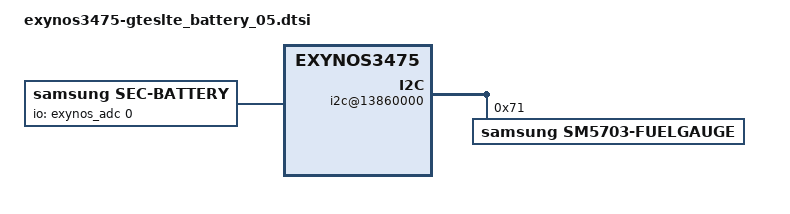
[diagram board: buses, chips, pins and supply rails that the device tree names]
/*
 * SAMSUNG UNIVERSAL5430 board device tree source
 *
 * Copyright (c) 2013 Samsung Electronics Co., Ltd.
 *		http://www.samsung.com
 *
 * This program is free software; you can redistribute it and/or modify
 * it under the terms of the GNU General Public License version 2 as
 * published by the Free Software Foundation.
*/

/ {
	pinctrl@139B0000 {
		fuel_irq: fuel-irq {
			samsung,pins = "gpa0-3";
			samsung,pin-function = <0>;
			samsung,pin-pud = <0>;
			samsung,pin-drv = <0>;
		};
	};

	i2c@13860000 {
		status = "okay";
		sm5703-fuelgauge@71 {
			compatible = "samsung,sm5703-fuelgauge";
			reg = <0x71>;
			pinctrl-names = "default";
			pinctrl-0 = <&fuel_irq>;
			fuelgauge,fuel_int = <&gpa0 3 0>;
			fuelgauge,fuel_alert_soc = <1>;
			fuelgauge,capacity_max = <1000>;
			fuelgauge,capacity_max_margin = <30>;
			fuelgauge,capacity_min = <0>;
			fuelgauge,capacity_calculation_type = <28>;
			fuelgauge,type_str = "SDI";
		};
	};

	battery_params {
		battery,id = <0>; /* -1 means auto, detected by F/G */
		battery0,battery_type = <4350>; /* 4200 4350 4400 */
		battery_table0 = <0x1400 0x1B99 0x1C89 0x1D43 0x1D80 0x1D8A 0x1DFD 0x1E77 0x1ECB 0x1F0C 0x1FA1 0x1FF8 0x208E 0x20A6 0x2270 0x2399>;
		battery_table1 = <0x1400 0x1B99 0x1C89 0x1D43 0x1D80 0x1D8A 0x1DFD 0x1E77 0x1ECB 0x1F0C 0x1FA1 0x1FF8 0x208E 0x20A6 0x2270 0x2399>;
		battery_table2 = <0x00 0x66 0x100 0x1CC 0x2C2 0x4C2 0x8B8 0x10A3 0x1499 0x168F 0x198F 0x1C85 0x1E7A 0x1F7A 0x2800 0x281E>;
		battery0,temp_std = <25>;
		battery0,temp_offset = <10>;
		battery0,temp_offset_cal = <0x01>;
		battery0,rce_value = <0x0749 0x0580 0x371>;
		battery0,dtcd_value = <0x1>;
		battery0,rs_value = <0x1ae 0x47a 0x3800 0x00a4>; /*rs mix_factor max min*/
		battery0,vit_period = <0x350a>;
		battery0,mix_value = <0x0503 0x0004>; /*mix_rate init_blank*/
		battery0,topoff_soc = <0x0 0x5>; /*disable soc*/
		battery0,volt_cal = <0x8000>;
		battery0,curr_cal = <0x8185>;
		battery0,charge_offset_cal = <(-0x04)>;
		battery0,tem_poff = <3400 100 3320 100>;
	};

	battery {
		status = "okay";

		pinctrl-names = "default";

		compatible = "samsung,sec-battery";
		battery,vendor = "SDI SDI";
		battery,charger_name = "sm5703-charger";
		battery,fuelgauge_name = "sm5703-fuelgauge";
		battery,technology = <2>; /* POWER_SUPPLY_TECHNOLOGY_LION */
		/* .temp_cohot = -1000; */
		/* .temp_cocold = -4325; */

		battery,chip_vendor = "LSI";
		battery,temp_adc_type = <1>; /* SEC_BATTERY_ADC_TYPE_AP */

		battery,polling_time = <10 30 30 30 3600>;

		battery,temp_table_adc = <430 445 461 476 492 507 523 539 554 570 586 606 625 645 664 684 706 729 751 774
					796 822 847 873 898 924 946 968 991 1013 1035 1072 1109 1146 1183 1220 1257 1295 1332 1370
					1407 1445 1484 1522 1561 1599 1640 1682 1723 1765 1806 1849 1892 1935 1978 2021 2064 2107 2150 2193
					2236 2286 2336 2385 2435 2485 2524 2564 2603 2643 2682 2728 2774 2819 2865 2911 2951 2992 3032 3073
					3113 3148 3183 3217 3252 3287 3317 3347 3378 3408 3438 3465 3492 3519 3546 3573 3594 3615 3636 3657 3678>;

		battery,temp_table_data = <800 790 780 770 760 750 740 730 720 710 700 690 680 670 660 650 640 630 620 610
					600 590 580 570 560 550 540 530 520 510 500 490 480 470 460 450 440 430 420 410
					400 390 380 370 360 350 340 330 320 310 300 290 280 270 260 250 240 230 220 210
					200 190 180 170 160 150 140 130 120 110 100 90 80 70 60 50 40 30 20 10
					0 (-10) (-20) (-30) (-40) (-50) (-60) (-70) (-80) (-90) (-100) (-110) (-120) (-130) (-140) (-150) (-160) (-170) (-180) (-190) (-200)>;

		battery,input_current_limit = <1800 0 0 1800 460 1800 1800 460 1800 0 1800 1800 1800 0 0 400 1800 1800 300 1800 1800 0 1800 1800 1800 80 1800 1800 1800 450>;
		battery,fast_charging_current = <2100 0 0 2100 460 2100 2100 460 2100 0 2100 2100 2100 0 0 400 2100 2100 300 2100 2100 0 2100 2100 2100 80 2100 2100 2100 450>;
		battery,full_check_current_1st = <250 0 0 250 250 250 250 250 250 0 250 250 250 0 0 250 250 250 250 250 250 0 250 250 250 0 250 250 250 250>;
		battery,full_check_current_2nd = <2400 0 0 2400 2400 2400 2400 2400 2400 0 2400 2400 2400 0 0 2400 2400 2400 2400 2400 2400 0 2400 2400 2400 2400 2400 2400 2400 2400>;

		battery,inbat_voltage = <0>;
		battery,inbat_voltage_table_adc = <3120 3101 3061 3038 3001 2956 2920 2887 2856 2814
						2793 2754 2720 2677 2641 2613 2572 2531 2502 2467 2436>;
		battery,inbat_voltage_table_data = <438 435 430 425 420 415 410 405 400 395
						390 385 380 375 370 365 360 355 350 345 340>;

		battery,adc_check_count = <5>;

		battery,cable_check_type = <5>; /* SEC_BATTERY_CABLE_CHECK_PSY */
		battery,cable_source_type = <1>; /* SEC_BATTERY_CABLE_SOURCE_EXTERNAL */
		battery,event_waiting_time = <600>;
		battery,polling_type = <1>; /* SEC_BATTERY_MONITOR_ALARM */
		battery,monitor_initial_count = <0>;

		battery,battery_check_type = <0>; /* SEC_BATTERY_CHECK_ADC */
		battery,check_count = <0>;
		battery,check_adc_max = <1440>;
		battery,check_adc_min = <0>;

		battery,ovp_uvlo_check_type = <3>; /* SEC_BATTERY_OVP_UVLO_CHGPOLLING */

		battery,thermal_source = <2>; /* SEC_BATTERY_THERMAL_SOURCE_ADC */

		battery,temp_check_type = <2>; /* SEC_BATTERY_TEMP_CHECK_TEMP */
		battery,temp_check_count = <1>;
		battery,temp_highlimit_threshold_event = <800>;
		battery,temp_highlimit_recovery_event = <750>;
		battery,temp_high_threshold_event = <580>;
		battery,temp_high_recovery_event = <530>;
		battery,temp_low_threshold_event = <(-50)>;
		battery,temp_low_recovery_event = <0>;
		battery,temp_highlimit_threshold_normal = <800>;
		battery,temp_highlimit_recovery_normal = <750>;
		battery,temp_high_threshold_normal = <580>;
		battery,temp_high_recovery_normal = <530>;
		battery,temp_low_threshold_normal = <(-50)>;
		battery,temp_low_recovery_normal = <0>;
		battery,temp_highlimit_threshold_lpm = <800>;
		battery,temp_highlimit_recovery_lpm = <750>;
		battery,temp_high_threshold_lpm = <580>;
		battery,temp_high_recovery_lpm = <530>;
		battery,temp_low_threshold_lpm = <(-50)>;
		battery,temp_low_recovery_lpm = <0>;

		battery,full_check_type = <2>; /* SEC_BATTERY_FULLCHARGED_FG_CURRENT */
		battery,full_check_type_2nd = <3>; /* SEC_BATTERY_FULLCHARGED_TIME */
		battery,full_check_count = <3>;
		battery,chg_gpio_full_check = <0>;
		battery,chg_polarity_full_check = <1>;

		/* SEC_BATTERY_FULL_CONDITION_SOC |
		   SEC_BATTERY_FULL_CONDITION_NOTIMEFULL |
		   SEC_BATTERY_FULL_CONDITION_VCELL */
		battery,full_condition_type = <13>;
		battery,full_condition_soc = <93>;
		battery,full_condition_vcell = <4250>;

		battery,recharge_check_count = <2>;
		battery,recharge_condition_type = <4>; /* SEC_BATTERY_RECHARGE_CONDITION_VCELL */
		battery,recharge_condition_soc = <98>;
		battery,recharge_condition_vcell = <4300>;

		battery,charging_total_time = <36000>;
		battery,recharging_total_time = <5400>;
		battery,charging_reset_time = <0>;

		battery,always_enable;

		io-channels = <&exynos_adc 0>;
		io-channel-names = "adc-temp";
		#io-channel-cells = <1>;
		io-channel-ranges;

		battery,chg_float_voltage = <4350>;

		battery,self_discharging_en;
		battery,force_discharging_limit = <650>;
		battery,force_discharging_recov = <550>;
		battery,self_discharging_voltage_limit = <4250>;
		battery,discharging_adc_max = <2600>;
		battery,discharging_adc_min = <1700>;
		battery,discharging_ntc_limit = <2750>;

		battery,swelling_high_temp_block = <500>;
		battery,swelling_high_temp_recov = <450>;
		battery,swelling_low_temp_block = <50>;
		battery,swelling_low_temp_recov = <100>;
		battery,swelling_chg_current = <900>;
		battery,swelling_drop_float_voltage = <4200>;
		battery,swelling_high_rechg_voltage = <4150>;
		battery,swelling_low_rechg_voltage = <4050>;
		battery,swelling_block_time = <600>;
	};

	charger {
		status = "disable";
		compatible = "siliconmitus,sm5703-charger";

		/* Charger */
		battery,charger_name = "sm5703-charger";
		battery,chg_gpio_en = <&gpd0 0 0>;
		battery,chg_polarity_en = <0>;
		battery,chg_gpio_status = <0>;
		battery,chg_polarity_status = <0>;
		battery,chg_float_voltage = <4350>;
		chg_autostop = <0>;
		chg_autoset = <1>;
		chg_aiclen = <1>;
		chg_aiclth = <4500>;
		fg_vol_val = <4350>;
		fg_soc_val = <95>;
		fg_curr_avr_val = <150>;
	};
};
